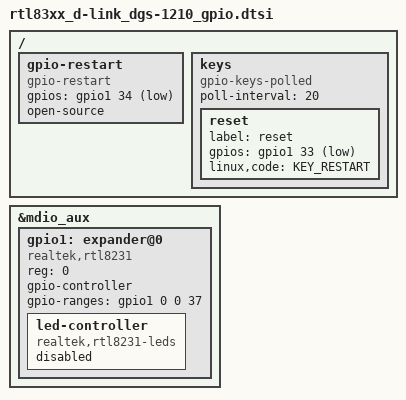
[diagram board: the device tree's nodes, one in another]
// SPDX-License-Identifier: GPL-2.0-or-later OR MIT

/ {
	gpio-restart {
		compatible = "gpio-restart";
		gpios = <&gpio1 34 GPIO_ACTIVE_LOW>;
		open-source;
	};

	keys: keys {
		compatible = "gpio-keys-polled";
		poll-interval = <20>;

		reset {
			label = "reset";
			gpios = <&gpio1 33 GPIO_ACTIVE_LOW>;
			linux,code = <KEY_RESTART>;
		};
	};
};

&mdio_aux {
	status = "okay";

	gpio1: expander@0 {
		compatible = "realtek,rtl8231";
		reg = <0>;

		gpio-controller;
		#gpio-cells = <2>;
		gpio-ranges = <&gpio1 0 0 37>;

		led-controller {
			compatible = "realtek,rtl8231-leds";
			status = "disabled";
		};
	};
};
